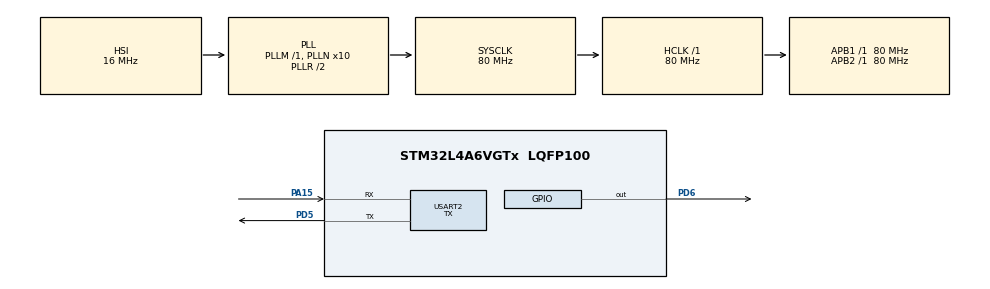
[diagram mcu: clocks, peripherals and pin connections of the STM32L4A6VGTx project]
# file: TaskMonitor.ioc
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FREERTOS.INCLUDE_uxTaskGetStackHighWaterMark2=1
FREERTOS.Queues01=defaultTaskQ,10,uint8_t,0,Static,defaultTaskQBuffer,defaultTaskQControlBlock;taskMonitorQ,10,uint8_t,0,Static,taskMonitorQBuffer,taskMonitorQControlBlock;task1Q,10,uint8_t,0,Static,task1QBuffer,task1QControlBlock;task2Q,10,uint8_t,0,Static,task2QBuffer,task2QControlBlock;task3Q,10,uint8_t,0,Static,task3QBuffer,task3QControlBlock
FREERTOS.Tasks01=defaultTask,24,256,StartDefaultTask,Default,NULL,Static,defaultTaskBuffer,defaultTaskControlBlock;taskMonitor,55,256,StartTaskMonitor,Default,NULL,Static,taskMonitorBuffer,taskMonitorControlBlock;Task1,48,256,StartTask1,Default,NULL,Static,Task1Buffer,Task1ControlBlock;Task2,40,256,StartTask2,Default,NULL,Static,Task2Buffer,Task2ControlBlock;Task3,32,256,StartTask3,Default,NULL,Static,Task3Buffer,Task3ControlBlock
FREERTOS.configCHECK_FOR_STACK_OVERFLOW=2
FREERTOS.configGENERATE_RUN_TIME_STATS=1
FREERTOS.configRECORD_STACK_HIGH_ADDRESS=1
FREERTOS.configUSE_STATS_FORMATTING_FUNCTIONS=1
IWDG.Prescaler=IWDG_PRESCALER_128
IWDG.Reload=2500
Mcu.Family=STM32L4
Mcu.Name=STM32L4A6VGTx
Mcu.Package=LQFP100
NVIC.PriorityGroup=NVIC_PRIORITYGROUP_4
PA15\ (JTDI).Mode=Asynchronous
PA15\ (JTDI).Signal=USART2_RX
PA3.Signal=ADCx_IN8
PC14-OSC32_IN\ (PC14).Mode=LSE-External-Oscillator
PC14-OSC32_IN\ (PC14).Signal=RCC_OSC32_IN
PC15-OSC32_OUT\ (PC15).Mode=LSE-External-Oscillator
PC15-OSC32_OUT\ (PC15).Signal=RCC_OSC32_OUT
PD5.Mode=Asynchronous
PD5.Signal=USART2_TX
PD6.Signal=GPIO_Output
ProjectManager.HeapSize=0x200
ProjectManager.StackSize=0x400
ProjectManager.TargetToolchain=STM32CubeIDE
RCC.ADCFreq_Value=64000000
RCC.AHBFreq_Value=80000000
RCC.APB1Freq_Value=80000000
RCC.APB1TimFreq_Value=80000000
RCC.APB2Freq_Value=80000000
RCC.APB2TimFreq_Value=80000000
RCC.CortexFreq_Value=80000000
RCC.HCLKFreq_Value=80000000
RCC.HSE_VALUE=8000000
RCC.HSI48_VALUE=48000000
RCC.HSICalibrationValue=64
RCC.HSI_VALUE=16000000
RCC.LPTIM1CLockSelection=RCC_LPTIM1CLKSOURCE_LSE
RCC.MSI_VALUE=4000000
RCC.PLLN=10
RCC.PLLSourceVirtual=RCC_PLLSOURCE_HSI
RCC.SYSCLKFreq_VALUE=80000000
RCC.SYSCLKSource=RCC_SYSCLKSOURCE_PLLCLK
RCC.USBFreq_Value=64000000
RCC.VCOOutputFreq_Value=160000000
SH.ADCx_IN8.0=ADC1_IN8
USART2.Mode=MODE_TX
USART2.VirtualMode-Asynchronous=VM_ASYNC
VP_FREERTOS_VS_CMSIS_V2.Mode=CMSIS_V2
VP_IWDG_VS_IWDG.Mode=IWDG_Activate
VP_LPTIM1_VS_LPTIM_counterModeInternalClock.Mode=Counts__internal_clock_event_00
board=custom

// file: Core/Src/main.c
/* USER CODE BEGIN Header */
/**
  ******************************************************************************
  * @file           : main.c
  * @brief          : Main program body
  ******************************************************************************
  * @attention
  *
  * Copyright (c) 2022 STMicroelectronics.
  * All rights reserved.
  *
  * This software is licensed under terms that can be found in the LICENSE file
  * in the root directory of this software component.
  * If no LICENSE file comes with this software, it is provided AS-IS.
  *
  ******************************************************************************
  */
/* USER CODE END Header */
#include "main.h"
#include "cmsis_os.h"
#include "lptim.h"
#include "usart.h"
#include "gpio.h"

void SystemClock_Config(void);
void MX_FREERTOS_Init(void);
/* USER CODE BEGIN PFP */
#define PUTCHAR_PROTOTYPE int __io_putchar(int ch)
/* USER CODE END PFP */

int main(void)
{

  /* MCU Configuration--------------------------------------------------------*/

  /* Reset of all peripherals, Initializes the Flash interface and the Systick. */
  HAL_Init();

  /* Configure the system clock */
  SystemClock_Config();

  /* Initialize all configured peripherals */
  MX_GPIO_Init();
  MX_USART2_UART_Init();
  MX_LPTIM1_Init();

  /* Init scheduler */
  osKernelInitialize();  /* Call init function for freertos objects (in freertos.c) */
  MX_FREERTOS_Init();

  /* Start scheduler */
  osKernelStart();

  /* We should never get here as control is now taken by the scheduler */
  /* Infinite loop */
  while (1)
  {

  }
}

void SystemClock_Config(void)
{
  RCC_OscInitTypeDef RCC_OscInitStruct = {0};
  RCC_ClkInitTypeDef RCC_ClkInitStruct = {0};

  /** Configure the main internal regulator output voltage
  */
  if (HAL_PWREx_ControlVoltageScaling(PWR_REGULATOR_VOLTAGE_SCALE1) != HAL_OK)
  {
    Error_Handler();
  }

  /** Configure LSE Drive Capability
  */
  HAL_PWR_EnableBkUpAccess();
  __HAL_RCC_LSEDRIVE_CONFIG(RCC_LSEDRIVE_LOW);

  /** Initializes the RCC Oscillators according to the specified parameters
  * in the RCC_OscInitTypeDef structure.
  */
  RCC_OscInitStruct.OscillatorType = RCC_OSCILLATORTYPE_HSI|RCC_OSCILLATORTYPE_LSE;
  RCC_OscInitStruct.LSEState = RCC_LSE_ON;
  RCC_OscInitStruct.HSIState = RCC_HSI_ON;
  RCC_OscInitStruct.HSICalibrationValue = RCC_HSICALIBRATION_DEFAULT;
  RCC_OscInitStruct.PLL.PLLState = RCC_PLL_ON;
  RCC_OscInitStruct.PLL.PLLSource = RCC_PLLSOURCE_HSI;
  RCC_OscInitStruct.PLL.PLLM = 1;
  RCC_OscInitStruct.PLL.PLLN = 10;
  RCC_OscInitStruct.PLL.PLLP = RCC_PLLP_DIV2;
  RCC_OscInitStruct.PLL.PLLQ = RCC_PLLQ_DIV2;
  RCC_OscInitStruct.PLL.PLLR = RCC_PLLR_DIV2;
  if (HAL_RCC_OscConfig(&RCC_OscInitStruct) != HAL_OK)
  {
    Error_Handler();
  }

  /** Initializes the CPU, AHB and APB buses clocks
  */
  RCC_ClkInitStruct.ClockType = RCC_CLOCKTYPE_HCLK|RCC_CLOCKTYPE_SYSCLK
                              |RCC_CLOCKTYPE_PCLK1|RCC_CLOCKTYPE_PCLK2;
  RCC_ClkInitStruct.SYSCLKSource = RCC_SYSCLKSOURCE_PLLCLK;
  RCC_ClkInitStruct.AHBCLKDivider = RCC_SYSCLK_DIV1;
  RCC_ClkInitStruct.APB1CLKDivider = RCC_HCLK_DIV1;
  RCC_ClkInitStruct.APB2CLKDivider = RCC_HCLK_DIV1;

  if (HAL_RCC_ClockConfig(&RCC_ClkInitStruct, FLASH_LATENCY_4) != HAL_OK)
  {
    Error_Handler();
  }
}

/* USER CODE BEGIN 4 */
/**
  * @brief  Retargets the C library printf function to the USART.
  * @param  None
  * @retval None
  */
PUTCHAR_PROTOTYPE
{
  /* Place your implementation of fputc here */
  /* e.g. write a character to the USART1 and Loop until the end of transmission */
  HAL_UART_Transmit(&huart2, (uint8_t *)&ch, 1, 0xFFFF);

  return ch;
}
/* USER CODE END 4 */

void Error_Handler(void)
{
  __disable_irq();
  while (1)
  {
  }
}

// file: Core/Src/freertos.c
/* USER CODE BEGIN Header */
/**
  ******************************************************************************
  * File Name          : freertos.c
  * Description        : Code for freertos applications
  ******************************************************************************
  * @attention
  *
  * Copyright (c) 2022 STMicroelectronics.
  * All rights reserved.
  *
  * This software is licensed under terms that can be found in the LICENSE file
  * in the root directory of this software component.
  * If no LICENSE file comes with this software, it is provided AS-IS.
  *
  ******************************************************************************
  */
/* USER CODE END Header */

#include "FreeRTOS.h"
#include "task.h"
#include "main.h"
#include "cmsis_os.h"

/* USER CODE BEGIN Includes */
#include "stdio.h"
#include "lptim.h"
/* USER CODE END Includes */

typedef StaticTask_t osStaticThreadDef_t;
typedef StaticQueue_t osStaticMessageQDef_t;

/* USER CODE BEGIN Variables */
static char taskListBuf[500];
static char taskStatsBuf[500];
/* USER CODE END Variables */
/* Definitions for defaultTask */
osThreadId_t defaultTaskHandle;
uint32_t defaultTaskBuffer[ 256 ];
osStaticThreadDef_t defaultTaskControlBlock;
const osThreadAttr_t defaultTask_attributes = {
  .name = "defaultTask",
  .cb_mem = &defaultTaskControlBlock,
  .cb_size = sizeof(defaultTaskControlBlock),
  .stack_mem = &defaultTaskBuffer[0],
  .stack_size = sizeof(defaultTaskBuffer),
  .priority = (osPriority_t) osPriorityNormal,
};
/* Definitions for taskMonitor */
osThreadId_t taskMonitorHandle;
uint32_t taskMonitorBuffer[ 256 ];
osStaticThreadDef_t taskMonitorControlBlock;
const osThreadAttr_t taskMonitor_attributes = {
  .name = "taskMonitor",
  .cb_mem = &taskMonitorControlBlock,
  .cb_size = sizeof(taskMonitorControlBlock),
  .stack_mem = &taskMonitorBuffer[0],
  .stack_size = sizeof(taskMonitorBuffer),
  .priority = (osPriority_t) osPriorityRealtime7,
};
/* Definitions for Task1 */
osThreadId_t Task1Handle;
uint32_t Task1Buffer[ 256 ];
osStaticThreadDef_t Task1ControlBlock;
const osThreadAttr_t Task1_attributes = {
  .name = "Task1",
  .cb_mem = &Task1ControlBlock,
  .cb_size = sizeof(Task1ControlBlock),
  .stack_mem = &Task1Buffer[0],
  .stack_size = sizeof(Task1Buffer),
  .priority = (osPriority_t) osPriorityRealtime,
};
/* Definitions for Task2 */
osThreadId_t Task2Handle;
uint32_t Task2Buffer[ 256 ];
osStaticThreadDef_t Task2ControlBlock;
const osThreadAttr_t Task2_attributes = {
  .name = "Task2",
  .cb_mem = &Task2ControlBlock,
  .cb_size = sizeof(Task2ControlBlock),
  .stack_mem = &Task2Buffer[0],
  .stack_size = sizeof(Task2Buffer),
  .priority = (osPriority_t) osPriorityHigh,
};
/* Definitions for Task3 */
osThreadId_t Task3Handle;
uint32_t Task3Buffer[ 256 ];
osStaticThreadDef_t Task3ControlBlock;
const osThreadAttr_t Task3_attributes = {
  .name = "Task3",
  .cb_mem = &Task3ControlBlock,
  .cb_size = sizeof(Task3ControlBlock),
  .stack_mem = &Task3Buffer[0],
  .stack_size = sizeof(Task3Buffer),
  .priority = (osPriority_t) osPriorityAboveNormal,
};
/* Definitions for defaultTaskQ */
osMessageQueueId_t defaultTaskQHandle;
uint8_t defaultTaskQBuffer[ 10 * sizeof( uint8_t ) ];
osStaticMessageQDef_t defaultTaskQControlBlock;
const osMessageQueueAttr_t defaultTaskQ_attributes = {
  .name = "defaultTaskQ",
  .cb_mem = &defaultTaskQControlBlock,
  .cb_size = sizeof(defaultTaskQControlBlock),
  .mq_mem = &defaultTaskQBuffer,
  .mq_size = sizeof(defaultTaskQBuffer)
};
/* Definitions for taskMonitorQ */
osMessageQueueId_t taskMonitorQHandle;
uint8_t taskMonitorQBuffer[ 10 * sizeof( uint8_t ) ];
osStaticMessageQDef_t taskMonitorQControlBlock;
const osMessageQueueAttr_t taskMonitorQ_attributes = {
  .name = "taskMonitorQ",
  .cb_mem = &taskMonitorQControlBlock,
  .cb_size = sizeof(taskMonitorQControlBlock),
  .mq_mem = &taskMonitorQBuffer,
  .mq_size = sizeof(taskMonitorQBuffer)
};
/* Definitions for task1Q */
osMessageQueueId_t task1QHandle;
uint8_t task1QBuffer[ 10 * sizeof( uint8_t ) ];
osStaticMessageQDef_t task1QControlBlock;
const osMessageQueueAttr_t task1Q_attributes = {
  .name = "task1Q",
  .cb_mem = &task1QControlBlock,
  .cb_size = sizeof(task1QControlBlock),
  .mq_mem = &task1QBuffer,
  .mq_size = sizeof(task1QBuffer)
};
/* Definitions for task2Q */
osMessageQueueId_t task2QHandle;
uint8_t task2QBuffer[ 10 * sizeof( uint8_t ) ];
osStaticMessageQDef_t task2QControlBlock;
const osMessageQueueAttr_t task2Q_attributes = {
  .name = "task2Q",
  .cb_mem = &task2QControlBlock,
  .cb_size = sizeof(task2QControlBlock),
  .mq_mem = &task2QBuffer,
  .mq_size = sizeof(task2QBuffer)
};
/* Definitions for task3Q */
osMessageQueueId_t task3QHandle;
uint8_t task3QBuffer[ 10 * sizeof( uint8_t ) ];
osStaticMessageQDef_t task3QControlBlock;
const osMessageQueueAttr_t task3Q_attributes = {
  .name = "task3Q",
  .cb_mem = &task3QControlBlock,
  .cb_size = sizeof(task3QControlBlock),
  .mq_mem = &task3QBuffer,
  .mq_size = sizeof(task3QBuffer)
};

void StartDefaultTask(void *argument);
void StartTaskMonitor(void *argument);
void StartTask1(void *argument);
void StartTask2(void *argument);
void StartTask3(void *argument);

void MX_FREERTOS_Init(void); /* (MISRA C 2004 rule 8.1) */

/* Hook prototypes */
void configureTimerForRunTimeStats(void);
unsigned long getRunTimeCounterValue(void);
void vApplicationStackOverflowHook(xTaskHandle xTask, signed char *pcTaskName);

/* USER CODE BEGIN 1 */
/* Functions needed when configGENERATE_RUN_TIME_STATS is on */
__weak void configureTimerForRunTimeStats(void)
{
    HAL_LPTIM_Counter_Start(&hlptim1, 0xFFFF);
}

static unsigned long lpCounter = 0;

__weak unsigned long getRunTimeCounterValue(void)
{

    static unsigned long prevLpCounter = 0;

    unsigned long currentLpCounter = HAL_LPTIM_ReadCounter(&hlptim1);;

    if (prevLpCounter > currentLpCounter)
    {
        lpCounter += (currentLpCounter + (0xFFFF - prevLpCounter));
    }
    else
    {
        lpCounter += (currentLpCounter - prevLpCounter);
    }

    prevLpCounter = currentLpCounter;

    return lpCounter;
}
/* USER CODE END 1 */

/* USER CODE BEGIN 4 */
void vApplicationStackOverflowHook(xTaskHandle xTask, signed char *pcTaskName)
{
   /* Run time stack overflow checking is performed if
   configCHECK_FOR_STACK_OVERFLOW is defined to 1 or 2. This hook function is
   called if a stack overflow is detected. */
}
/* USER CODE END 4 */

void MX_FREERTOS_Init(void) {

  /* Create the queue(s) */
  /* creation of defaultTaskQ */
  defaultTaskQHandle = osMessageQueueNew (10, sizeof(uint8_t), &defaultTaskQ_attributes);

  /* creation of taskMonitorQ */
  taskMonitorQHandle = osMessageQueueNew (10, sizeof(uint8_t), &taskMonitorQ_attributes);

  /* creation of task1Q */
  task1QHandle = osMessageQueueNew (10, sizeof(uint8_t), &task1Q_attributes);

  /* creation of task2Q */
  task2QHandle = osMessageQueueNew (10, sizeof(uint8_t), &task2Q_attributes);

  /* creation of task3Q */
  task3QHandle = osMessageQueueNew (10, sizeof(uint8_t), &task3Q_attributes);

  /* Create the thread(s) */
  /* creation of defaultTask */
  defaultTaskHandle = osThreadNew(StartDefaultTask, NULL, &defaultTask_attributes);

  /* creation of taskMonitor */
  taskMonitorHandle = osThreadNew(StartTaskMonitor, NULL, &taskMonitor_attributes);

  /* creation of Task1 */
  Task1Handle = osThreadNew(StartTask1, NULL, &Task1_attributes);

  /* creation of Task2 */
  Task2Handle = osThreadNew(StartTask2, NULL, &Task2_attributes);

  /* creation of Task3 */
  Task3Handle = osThreadNew(StartTask3, NULL, &Task3_attributes);

}

void StartDefaultTask(void *argument)
{
  /* USER CODE BEGIN StartDefaultTask */
  /* Infinite loop */
  for(;;)
  {
      printf("LP Counter: %lu\r\n\r\n", lpCounter);

      vTaskList(taskListBuf);
      printf("TASK INFO**********************************************\r\n");
      printf("Name          State  Priority   Stack   Num\r\n");
      printf("*******************************************\r\n");
      printf("%s\r\n", taskListBuf);
      printf("\r\n");

      vTaskGetRunTimeStats(taskStatsBuf);
      printf("TASK STATS INFO****************************************\r\n");
      printf("Name             Abs Time       %% Time\r\n");
      printf("*******************************************\r\n");
      printf("%s\r\n", taskStatsBuf);
      printf("\r\n");

      osDelay(10000);
  }
  /* USER CODE END StartDefaultTask */
}

void StartTaskMonitor(void *argument)
{
  /* USER CODE BEGIN StartTaskMonitor */
  /* Infinite loop */
  for(;;)
  {
    osDelay(10);
  }
  /* USER CODE END StartTaskMonitor */
}

void StartTask1(void *argument)
{
  /* USER CODE BEGIN StartTask1 */
    int count = 0;
  /* Infinite loop */
  for(;;)
  {
//      printf("Task1: %d\r\n", count++);
    osDelay(500);
  }
  /* USER CODE END StartTask1 */
}

void StartTask2(void *argument)
{
  /* USER CODE BEGIN StartTask2 */
    int count = 0;
  /* Infinite loop */
  for(;;)
  {
//      printf("Task2: %d\r\n", count++);
    osDelay(250);
  }
  /* USER CODE END StartTask2 */
}

void StartTask3(void *argument)
{
  /* USER CODE BEGIN StartTask3 */
    int count = 0;
  /* Infinite loop */
  for(;;)
  {
//      printf("Task3: %d\r\n", count++);
    osDelay(100);
  }
  /* USER CODE END StartTask3 */
}
